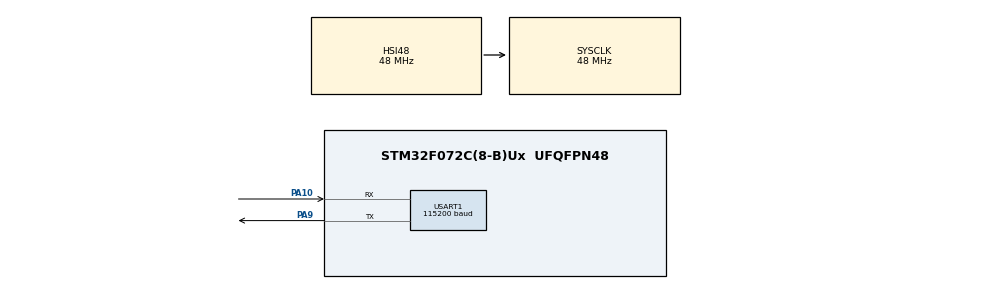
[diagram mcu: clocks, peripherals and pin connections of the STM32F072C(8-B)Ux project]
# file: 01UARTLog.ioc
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Mcu.Family=STM32F0
Mcu.Name=STM32F072C(8-B)Ux
Mcu.Package=UFQFPN48
PA10.Mode=Asynchronous
PA10.Signal=USART1_RX
PA13.Mode=Serial_Wire
PA13.Signal=SYS_SWDIO
PA14.Mode=Serial_Wire
PA14.Signal=SYS_SWCLK
PA9.Mode=Asynchronous
PA9.Signal=USART1_TX
ProjectManager.HeapSize=0x200
ProjectManager.StackSize=0x400
ProjectManager.TargetToolchain=MDK-ARM V5.32
RCC.SYSCLKFreq_VALUE=48000000
RCC.SYSCLKSource=RCC_SYSCLKSOURCE_HSI48
USART1.BaudRate=115200
USART1.VirtualMode-Asynchronous=VM_ASYNC
board=custom

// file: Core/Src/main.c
/* USER CODE BEGIN Header */
/**
  ******************************************************************************
  * @file           : main.c
  * @brief          : Main program body
  ******************************************************************************
  * @attention
  *
  * Copyright (c) 2026 STMicroelectronics.
  * All rights reserved.
  *
  * This software is licensed under terms that can be found in the LICENSE file
  * in the root directory of this software component.
  * If no LICENSE file comes with this software, it is provided AS-IS.
  *
  ******************************************************************************
  */
/* USER CODE END Header */
#include "main.h"

/* USER CODE BEGIN Includes */
#include <stdio.h>
/*
 * 示例名称：USART1 周期日志
 * 目标芯片：STM32F072CBU6；系统时钟 HSI 8 MHz。
 * USART1 使用 PA9(TX)/PA10(RX)，参数为 115200、8 数据位、无校验、
 * 1 停止位、无硬件流控。PA9 应连接 3.3 V USB-UART 的 RX，并共地。
 * 上电后打印芯片和时钟信息，之后每秒打印运行时间与递增计数。
 */
/* USER CODE END Includes */

UART_HandleTypeDef huart1;

/* USER CODE BEGIN PV */
/* 已输出的周期日志计数；达到 uint32_t 上限后会按无符号整数规则回绕。 */
static uint32_t app_counter;
/* USER CODE END PV */

void SystemClock_Config(void);
static void MX_GPIO_Init(void);
static void MX_USART1_UART_Init(void);
/* USER CODE BEGIN PFP */
static void App_Init(void);
static void App_Loop(void);
/* USER CODE END PFP */

/* USER CODE BEGIN 0 */
/**
 * @brief 将 printf 输出重定向到 USART1
 *
 * newlib 的 printf 最终调用本函数。发送采用轮询阻塞方式，超时为 100 ms；
 * 日志过长或串口异常会延长主循环执行时间，因此不适合高实时性路径或中断。
 */
int _write(int file, char *ptr, int len)
{
  (void)file;
  if ((ptr == NULL) || (len <= 0)) return 0;
  return (HAL_UART_Transmit(&huart1, (uint8_t *)ptr, (uint16_t)len, 100U) == HAL_OK) ? len : -1;
}
#if defined(__CC_ARM) || defined(__ARMCC_VERSION)
int fputc(int ch, FILE *stream)
{
  uint8_t byte = (uint8_t)ch;
  (void)stream;
  return (HAL_UART_Transmit(&huart1, &byte, 1U, 100U) == HAL_OK) ? ch : EOF;
}
#endif
/** @brief 输出启动信息；底层 UART 已由 MX_USART1_UART_Init() 完成初始化。 */
static void App_Init(void)
{
  printf("\r\nSTM32F072CBU6 UART Log Example\r\nSystemCoreClock: %lu Hz\r\n", (unsigned long)SystemCoreClock);
}
/** @brief 每等待一秒更新计数，并输出 HAL 毫秒节拍换算得到的运行秒数。 */
static void App_Loop(void)
{
  HAL_Delay(1000U);
  ++app_counter;
  printf("Uptime: %lu s, Counter: %lu\r\n", (unsigned long)(HAL_GetTick()/1000U), (unsigned long)app_counter);
}
/* USER CODE END 0 */

int main(void)
{

  /* MCU Configuration--------------------------------------------------------*/

  /* Reset of all peripherals, Initializes the Flash interface and the Systick. */
  HAL_Init();

  /* Configure the system clock */
  SystemClock_Config();

  /* Initialize all configured peripherals */
  MX_GPIO_Init();
  MX_USART1_UART_Init();
  /* USER CODE BEGIN 2 */
  App_Init();
  /* USER CODE END 2 */

  /* Infinite loop */
  /* USER CODE BEGIN WHILE */
  while (1)
  {
    App_Loop();
    /* USER CODE END WHILE */

  }
}

void SystemClock_Config(void)
{
  RCC_OscInitTypeDef RCC_OscInitStruct = {0};
  RCC_ClkInitTypeDef RCC_ClkInitStruct = {0};
  RCC_PeriphCLKInitTypeDef PeriphClkInit = {0};

  /** Initializes the RCC Oscillators according to the specified parameters
  * in the RCC_OscInitTypeDef structure.
  */
  RCC_OscInitStruct.OscillatorType = RCC_OSCILLATORTYPE_HSI48;
  RCC_OscInitStruct.HSI48State = RCC_HSI48_ON;
  RCC_OscInitStruct.PLL.PLLState = RCC_PLL_NONE;
  if (HAL_RCC_OscConfig(&RCC_OscInitStruct) != HAL_OK)
  {
    Error_Handler();
  }

  /** Initializes the CPU, AHB and APB buses clocks
  */
  RCC_ClkInitStruct.ClockType = RCC_CLOCKTYPE_HCLK|RCC_CLOCKTYPE_SYSCLK
                              |RCC_CLOCKTYPE_PCLK1;
  RCC_ClkInitStruct.SYSCLKSource = RCC_SYSCLKSOURCE_HSI48;
  RCC_ClkInitStruct.AHBCLKDivider = RCC_SYSCLK_DIV1;
  RCC_ClkInitStruct.APB1CLKDivider = RCC_HCLK_DIV1;

  if (HAL_RCC_ClockConfig(&RCC_ClkInitStruct, FLASH_LATENCY_1) != HAL_OK)
  {
    Error_Handler();
  }
  PeriphClkInit.PeriphClockSelection = RCC_PERIPHCLK_USART1;
  PeriphClkInit.Usart1ClockSelection = RCC_USART1CLKSOURCE_PCLK1;
  if (HAL_RCCEx_PeriphCLKConfig(&PeriphClkInit) != HAL_OK)
  {
    Error_Handler();
  }
}

static void MX_USART1_UART_Init(void)
{

  huart1.Instance = USART1;
  huart1.Init.BaudRate = 115200;
  huart1.Init.WordLength = UART_WORDLENGTH_8B;
  huart1.Init.StopBits = UART_STOPBITS_1;
  huart1.Init.Parity = UART_PARITY_NONE;
  huart1.Init.Mode = UART_MODE_TX_RX;
  huart1.Init.HwFlowCtl = UART_HWCONTROL_NONE;
  huart1.Init.OverSampling = UART_OVERSAMPLING_16;
  huart1.Init.OneBitSampling = UART_ONE_BIT_SAMPLE_DISABLE;
  huart1.AdvancedInit.AdvFeatureInit = UART_ADVFEATURE_NO_INIT;
  if (HAL_UART_Init(&huart1) != HAL_OK)
  {
    Error_Handler();
  }

}

static void MX_GPIO_Init(void)
{

  /* GPIO Ports Clock Enable */
  __HAL_RCC_GPIOA_CLK_ENABLE();

}

void Error_Handler(void)
{
  __disable_irq();
  while (1)
  {
  }
}
